# CH583SFR register map
Vendor: WCH Ltd.; Series: CH58x; File version: 1.1
CPU: RISC-V r0p0, little endian, no MPU, no FPU, 2 interrupt priority bits
Registers are 8-bit, read-write, reset 0x0 unless marked. A register's access mark holds for its fields unless they carry their own. Offsets are from the block's base; [hi:lo] are bit positions.

## GPIOA — System Control Register
Base 0x40001000
0x90 R16_PA_INT_EN 16-bit — RW, GPIO PA interrupt enable
  [15:0] R16_PA_INT_EN — GPIO PA interrupt enable
0x94 R16_PA_INT_MODE 16-bit — RW, GPIO PA interrupt mode: 0=level action, 1=edge action
  [15:0] R16_PA_INT_MODE — GPIO PA interrupt mode
0x9C R16_PA_INT_IF 16-bit — RW1, GPIO PA interrupt flag
  [15:0] R16_PA_INT_IF — GPIO PA interrupt flag
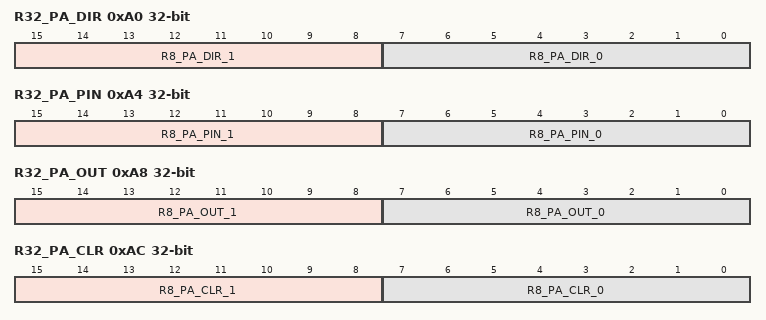
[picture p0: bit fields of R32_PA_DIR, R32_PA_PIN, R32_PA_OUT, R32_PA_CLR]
0xA0 R32_PA_DIR 32-bit — RW, GPIO PA I/O direction: 0=in, 1=out
  [15:8] R8_PA_DIR_1 — GPIO PA I/O direction byte 1
  [7:0] R8_PA_DIR_0 — GPIO PA I/O direction byte 0
0xA4 R32_PA_PIN 32-bit ro — RO, GPIO PA input
  [15:8] R8_PA_PIN_1 — GPIO PA input byte 1
  [7:0] R8_PA_PIN_0 — GPIO PA input byte 0
0xA8 R32_PA_OUT 32-bit — RW, GPIO PA output
  [15:8] R8_PA_OUT_1 — GPIO PA output byte 1
  [7:0] R8_PA_OUT_0 — GPIO PA output byte 0
0xAC R32_PA_CLR 32-bit — WZ, GPIO PA clear output: 0=keep, 1=clear
  [15:8] R8_PA_CLR_1 — GPIO PA clear output byte 1
  [7:0] R8_PA_CLR_0 — GPIO PA clear output byte 0
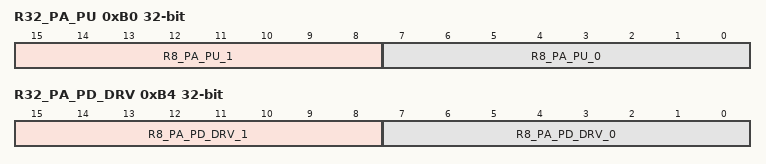
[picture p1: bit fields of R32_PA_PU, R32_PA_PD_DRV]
0xB0 R32_PA_PU 32-bit — RW, GPIO PA pullup resistance enable
  [15:8] R8_PA_PU_1 — GPIO PA pullup resistance enable byte 0
  [7:0] R8_PA_PU_0 — GPIO PA pullup resistance enable byte 0
0xB4 R32_PA_PD_DRV 32-bit — RW, PA pulldown for input or PA driving capability for output
  [15:8] R8_PA_PD_DRV_1 — PA pulldown for input or PA driving capability for output byte 1
  [7:0] R8_PA_PD_DRV_0 — PA pulldown for input or PA driving capability for output byte 0

## GPIOB — System Control Register
Base 0x40001000
0x92 R16_PB_INT_EN 16-bit — RW, GPIO PB interrupt enable
  [15:0] R16_PB_INT_EN — GPIO PB interrupt enable
0x96 R16_PB_INT_MODE 16-bit — RW, GPIO PB interrupt mode: 0=level action, 1=edge action
  [15:0] R16_PB_INT_MODE — GPIO PB interrupt mode
0x9E R16_PB_INT_IF 16-bit — RW1, GPIO PB interrupt flag
  [15:0] R16_PB_INT_IF — GPIO PB interrupt flag
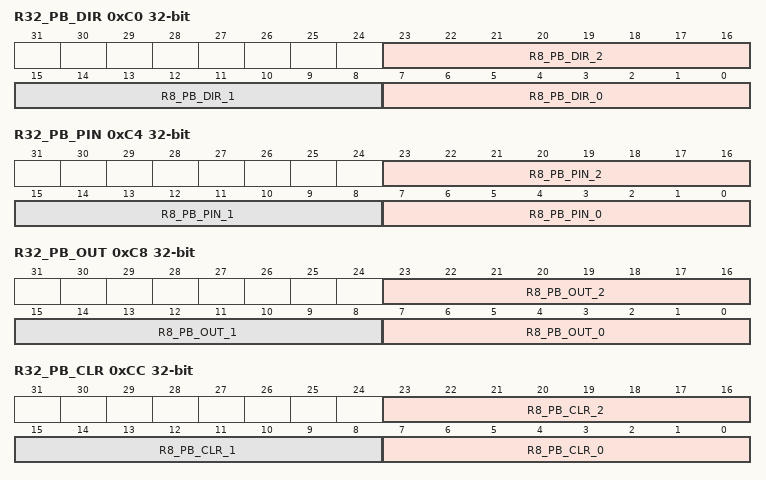
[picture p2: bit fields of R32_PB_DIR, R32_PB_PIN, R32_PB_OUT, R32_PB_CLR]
0xC0 R32_PB_DIR 32-bit — RW, GPIO PB I/O direction: 0=in, 1=out
  [23:16] R8_PB_DIR_2 — GPIO PB I/O direction byte 2
  [15:8] R8_PB_DIR_1 — GPIO PB I/O direction byte 1
  [7:0] R8_PB_DIR_0 — GPIO PB I/O direction byte 0
0xC4 R32_PB_PIN 32-bit ro — RO, GPIO PB input
  [23:16] R8_PB_PIN_2 — GPIO PB input byte 2
  [15:8] R8_PB_PIN_1 — GPIO PB input byte 1
  [7:0] R8_PB_PIN_0 — GPIO PB input byte 0
0xC8 R32_PB_OUT 32-bit — RW, GPIO PB output
  [23:16] R8_PB_OUT_2 — GPIO PB output byte 2
  [15:8] R8_PB_OUT_1 — GPIO PB output byte 1
  [7:0] R8_PB_OUT_0 — GPIO PB output byte 0
0xCC R32_PB_CLR 32-bit — WZ, GPIO PB clear output: 0=keep, 1=clear
  [23:16] R8_PB_CLR_2 — GPIO PB clear output byte 2
  [15:8] R8_PB_CLR_1 — GPIO PB clear output byte 1
  [7:0] R8_PB_CLR_0 — GPIO PB clear output byte 0
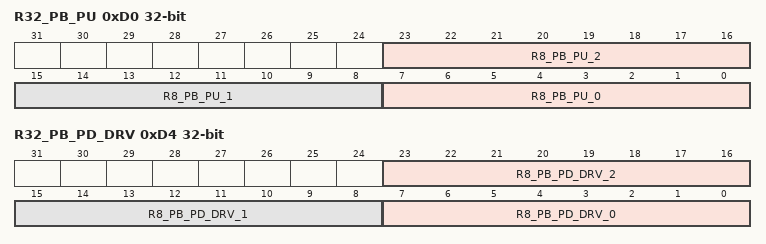
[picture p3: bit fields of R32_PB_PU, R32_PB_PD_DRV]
0xD0 R32_PB_PU 32-bit — RW, GPIO PB pullup resistance enable
  [23:16] R8_PB_PU_2 — GPIO PB pullup resistance enable byte 2
  [15:8] R8_PB_PU_1 — GPIO PB pullup resistance enable byte 1
  [7:0] R8_PB_PU_0 — GPIO PB pullup resistance enable byte 0
0xD4 R32_PB_PD_DRV 32-bit — RW, PB pulldown for input or PB driving capability for output
  [23:16] R8_PB_PD_DRV_2 — PB pulldown for input or PB driving capability for output byte 0
  [15:8] R8_PB_PD_DRV_1 — PB pulldown for input or PB driving capability for output byte 0
  [7:0] R8_PB_PD_DRV_0 — PB pulldown for input or PB driving capability for output byte 0

## TMR2 — Timer2 register
Base 0x40002800
0x00 R8_TMR2_CTRL_MOD reset 0x2 — RW, TMR2 mode control
  [7:6] RB_TMR_PWM_REPEAT — RW, timer PWM repeat mode: 00=1, 01=4, 10=8, 11-16
  [7:6] RB_TMR_CAP_EDGE — RW, timer capture edge mode: 00=disable, 01=edge change, 10=fall to fall, 11-rise to rise
  [4] RB_TMR_OUT_POLAR — RW, timer PWM output polarity: 0=default low and high action, 1=default high and low action
  [4] RB_TMR_CAP_COUNT — RW, count sub-mode if RB_TMR_MODE_IN=1: 0=capture, 1=count
  [3] RB_TMR_OUT_EN — RW, timer output enable
  [2] RB_TMR_COUNT_EN — RW, timer count enable
  [1] RB_TMR_ALL_CLEAR — RW, force clear timer FIFO and count
  [0] RB_TMR_MODE_IN — RW, timer in mode: 0=timer_PWM, 1=capture_count
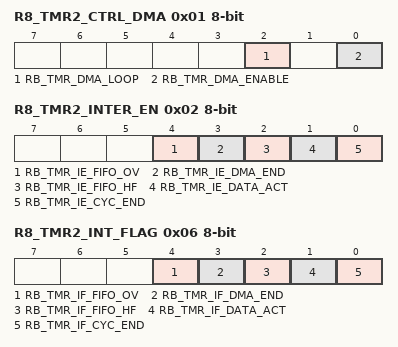
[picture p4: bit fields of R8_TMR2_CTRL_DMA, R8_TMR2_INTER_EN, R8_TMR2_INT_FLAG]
0x01 R8_TMR2_CTRL_DMA — RW, TMR2 DMA control
  [2] RB_TMR_DMA_LOOP — RW, timer1_2 DMA address loop enable
  [0] RB_TMR_DMA_ENABLE — RW, timer1_2 DMA enable
0x02 R8_TMR2_INTER_EN — RW, TMR2 interrupt enable
  [4] RB_TMR_IE_FIFO_OV — RW, enable interrupt for timer FIFO overflow
  [3] RB_TMR_IE_DMA_END — RW, enable interrupt for timer1/2 DMA completion
  [2] RB_TMR_IE_FIFO_HF — RW, enable interrupt for timer FIFO half (capture fifo >=4 or PWM fifo less than 3)
  [1] RB_TMR_IE_DATA_ACT — RW, enable interrupt for timer capture input action or PWM trigger
  [0] RB_TMR_IE_CYC_END — RW, enable interrupt for timer capture count timeout or PWM cycle end
0x06 R8_TMR2_INT_FLAG — RW1, TMR2 interrupt flag
  [4] RB_TMR_IF_FIFO_OV — RW1, interrupt flag for timer FIFO overflow
  [3] RB_TMR_IF_DMA_END — RW1, interrupt flag for timer1/2 DMA completion
  [2] RB_TMR_IF_FIFO_HF — RW1, interrupt flag for timer FIFO half (capture fifo >=4 or PWM fifo less than 3
  [1] RB_TMR_IF_DATA_ACT — RW1, interrupt flag for timer capture input action or PWM trigger
  [0] RB_TMR_IF_CYC_END — RW1, interrupt flag for timer capture count timeout or PWM cycle end
0x07 R8_TMR2_FIFO_COUNT ro (reset mask 0xF0) — RO, TMR2 FIFO count status
  [7:0] R8_TMR2_FIFO_COUNT — RW, TMR2 FIFO count status
0x08 R32_TMR2_COUNT 32-bit ro (reset mask 0xF0) — RO, TMR2 current count
  [31:0] R32_TMR2_COUNT — RW, TMR2 current count
0x0C R32_TMR2_CNT_END 32-bit (reset mask 0xF0) — RW, TMR2 end count value, only low 26 bit
  [31:0] R32_TMR2_CNT_END — RW, TMR2 current count
0x10 R32_TMR2_FIFO 32-bit — RO, TMR2 FIFO register, only low 26 bit
  [31:0] R32_TMR2_FIFO — RW, TMR2 current count
0x14 R16_TMR2_DMA_NOW 16-bit ro — RO, TMR2 DMA current address
  [15:0] R16_TMR2_DMA_NOW — RW, TMR2 current count
0x18 R16_TMR2_DMA_BEG 16-bit — RW, TMR2 DMA begin address
0x1C R16_TMR2_DMA_END 16-bit — RW, TMR2 DMA end address
